# core register map
Vendor: litex
Registers are 32-bit, read-write, reset 0x0 unless marked. A register's access mark holds for its fields unless they carry their own. Offsets are from the block's base; [hi:lo] are bit positions; {n}, {i} and the like mark numbered series.

## IRQARRAY11
Base 0xE0007000
0x00 EV_SOFT — Software interrupt trigger register. ) Bits set to `1` will trigger an interrupt. Interrupts trigger on write, but the value will persist in the register, allowing software to determine if a software interrupt was triggered by reading back the register. Software is responsible for clearing the register to 0. Repeated `1` writes without clearing will still trigger an interrupt.
  [15:0] trigger
0x04 EV_EDGE_TRIGGERED — If a bit is set to 1, then the hardware trigger is edge-triggered
  [15:0] use_edge
0x08 EV_POLARITY — If a bit is set to 1, then the polarity is rising edge triggered; 0 is falling edge triggered. Bit is ignored if `edge_triggered` is 0.
  [15:0] rising
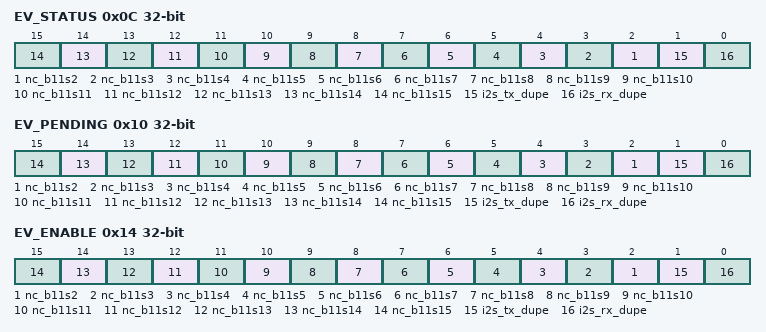
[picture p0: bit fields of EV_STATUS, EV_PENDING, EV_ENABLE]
0x0C EV_STATUS — `1` when a "nc_b11s15" event occurs. This event uses an `EventSourceFlex` form of triggering
  [n] nc_b11s{n} (n=2..15) — Level of the ``nc_b11s{n}`` event
  [1] i2s_tx_dupe — Level of the ``i2s_tx_dupe`` event
  [0] i2s_rx_dupe — Level of the ``i2s_rx_dupe`` event
0x10 EV_PENDING — `1` when a "nc_b11s15" event occurs. This event uses an `EventSourceFlex` form of triggering
  [n] nc_b11s{n} (n=2..15) — `1` when a "nc_b11s{n}" event occurs. This event uses an `EventSourceFlex` form of triggering
  [1] i2s_tx_dupe — `1` when a "i2s_tx_dupe" event occurs. This event uses an `EventSourceFlex` form of triggering
  [0] i2s_rx_dupe — `1` when a "i2s_rx_dupe" event occurs. This event uses an `EventSourceFlex` form of triggering
0x14 EV_ENABLE — `1` when a "nc_b11s15" event occurs. This event uses an `EventSourceFlex` form of triggering
  [n] nc_b11s{n} (n=2..15) — Write a ``1`` to enable the ``nc_b11s{n}`` Event
  [1] i2s_tx_dupe — Write a ``1`` to enable the ``i2s_tx_dupe`` Event
  [0] i2s_rx_dupe — Write a ``1`` to enable the ``i2s_rx_dupe`` Event

## IRQARRAY12
Base 0xE0008000
0x00 EV_SOFT — Software interrupt trigger register. ) Bits set to `1` will trigger an interrupt. Interrupts trigger on write, but the value will persist in the register, allowing software to determine if a software interrupt was triggered by reading back the register. Software is responsible for clearing the register to 0. Repeated `1` writes without clearing will still trigger an interrupt.
  [15:0] trigger
0x04 EV_EDGE_TRIGGERED — If a bit is set to 1, then the hardware trigger is edge-triggered
  [15:0] use_edge
0x08 EV_POLARITY — If a bit is set to 1, then the polarity is rising edge triggered; 0 is falling edge triggered. Bit is ignored if `edge_triggered` is 0.
  [15:0] rising
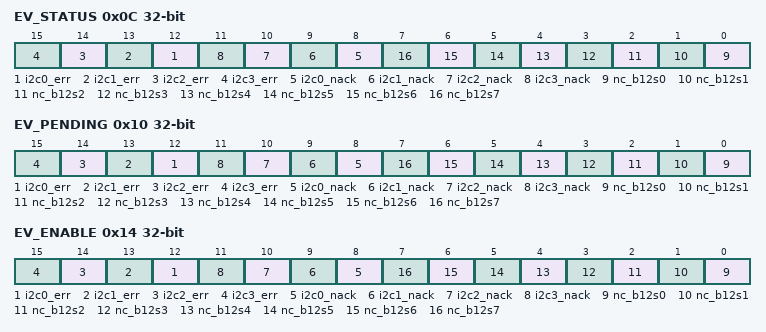
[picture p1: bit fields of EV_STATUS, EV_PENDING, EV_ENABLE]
0x0C EV_STATUS — `1` when a "i2c3_err" event occurs. This event uses an `EventSourceFlex` form of triggering
  [n+12] i2c{n}_err (n=0..3) — Level of the ``i2c{n}_err`` event
  [n+8] i2c{n}_nack (n=0..3) — Level of the ``i2c{n}_nack`` event
  [n] nc_b12s{n} (n=0..7) — Level of the ``nc_b12s{n}`` event
0x10 EV_PENDING — `1` when a "i2c3_err" event occurs. This event uses an `EventSourceFlex` form of triggering
  [n+12] i2c{n}_err (n=0..3) — `1` when a "i2c{n}_err" event occurs. This event uses an `EventSourceFlex` form of triggering
  [n+8] i2c{n}_nack (n=0..3) — `1` when a "i2c{n}_nack" event occurs. This event uses an `EventSourceFlex` form of triggering
  [n] nc_b12s{n} (n=0..7) — `1` when a "nc_b12s{n}" event occurs. This event uses an `EventSourceFlex` form of triggering
0x14 EV_ENABLE — `1` when a "i2c3_err" event occurs. This event uses an `EventSourceFlex` form of triggering
  [n+12] i2c{n}_err (n=0..3) — Write a ``1`` to enable the ``i2c{n}_err`` Event
  [n+8] i2c{n}_nack (n=0..3) — Write a ``1`` to enable the ``i2c{n}_nack`` Event
  [n] nc_b12s{n} (n=0..7) — Write a ``1`` to enable the ``nc_b12s{n}`` Event

## IRQARRAY13
Base 0xE0009000
0x00 EV_SOFT — Software interrupt trigger register. ) Bits set to `1` will trigger an interrupt. Interrupts trigger on write, but the value will persist in the register, allowing software to determine if a software interrupt was triggered by reading back the register. Software is responsible for clearing the register to 0. Repeated `1` writes without clearing will still trigger an interrupt.
  [15:0] trigger
0x04 EV_EDGE_TRIGGERED — If a bit is set to 1, then the hardware trigger is edge-triggered
  [15:0] use_edge
0x08 EV_POLARITY — If a bit is set to 1, then the polarity is rising edge triggered; 0 is falling edge triggered. Bit is ignored if `edge_triggered` is 0.
  [15:0] rising
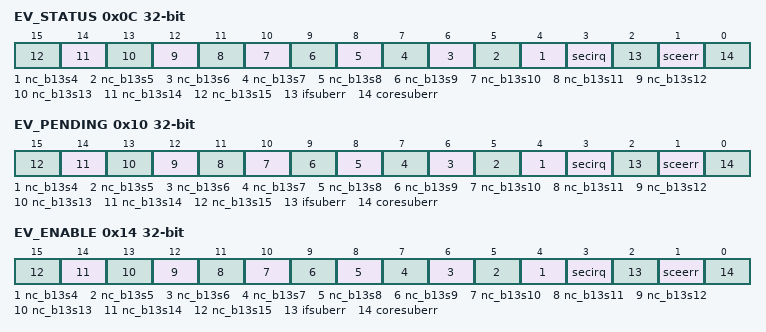
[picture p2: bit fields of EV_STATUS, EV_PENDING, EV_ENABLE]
0x0C EV_STATUS — `1` when a "nc_b13s15" event occurs. This event uses an `EventSourceFlex` form of triggering
  [n] nc_b13s{n} (n=4..15) — Level of the ``nc_b13s{n}`` event
  [3] secirq — Level of the ``secirq`` event
  [2] ifsuberr — Level of the ``ifsuberr`` event
  [1] sceerr — Level of the ``sceerr`` event
  [0] coresuberr — Level of the ``coresuberr`` event
0x10 EV_PENDING — `1` when a "nc_b13s15" event occurs. This event uses an `EventSourceFlex` form of triggering
  [n] nc_b13s{n} (n=4..15) — `1` when a "nc_b13s{n}" event occurs. This event uses an `EventSourceFlex` form of triggering
  [3] secirq — `1` when a "secirq" event occurs. This event uses an `EventSourceFlex` form of triggering
  [2] ifsuberr — `1` when a "ifsuberr" event occurs. This event uses an `EventSourceFlex` form of triggering
  [1] sceerr — `1` when a "sceerr" event occurs. This event uses an `EventSourceFlex` form of triggering
  [0] coresuberr — `1` when a "coresuberr" event occurs. This event uses an `EventSourceFlex` form of triggering
0x14 EV_ENABLE — `1` when a "nc_b13s15" event occurs. This event uses an `EventSourceFlex` form of triggering
  [n] nc_b13s{n} (n=4..15) — Write a ``1`` to enable the ``nc_b13s{n}`` Event
  [3] secirq — Write a ``1`` to enable the ``secirq`` Event
  [2] ifsuberr — Write a ``1`` to enable the ``ifsuberr`` Event
  [1] sceerr — Write a ``1`` to enable the ``sceerr`` Event
  [0] coresuberr — Write a ``1`` to enable the ``coresuberr`` Event
